# Parashu register map
Vendor: Shakti; Series: Shakti SoC
Shakti SoC, 32-bit RV32IMAC core on arty7 100T
CPU: Parashu, little endian
Registers are 32-bit, read-write, reset 0x0 unless marked. A register's access mark holds for its fields unless they carry their own. Offsets are from the block's base; lines under a group give offsets from that group; [hi:lo] are bit positions; {n}, {i} and the like mark numbered series; 'fields as' and 'values as' point back to an identical list; <NAME> marks a mode.

## Memory map
0x00011300 UART0 size 0x100 — Universal Asynchronous Receiver/Transmitter.
0x00011400 UART1 size 0x100 — Universal Asynchronous Receiver/Transmitter.
0x00011500 UART2 size 0x100 — Universal Asynchronous Receiver/Transmitter.
0x00020000 SPI0 size 0x100
0x00020100 SPI1 size 0x100
0x00030000 PWM0 size 0x100 — Pulse-Width Modulation.
0x00030100 PWM1 size 0x100
0x00030200 PWM2 size 0x100
0x00030300 PWM3 size 0x100
0x00030400 PWM4 size 0x100
0x00030500 PWM5 size 0x100
0x00040000 I2C0 size 0x100
0x00040100 GPIO0 size 0x1000 — General purpose input/output controller.
0x00041400 I2C1 size 0x100
0x0C000000 PLIC size 0x200008 — Platform-Level Interrupt Controller.
0x20000000 CLINT size 0x10000 — Core Local Interruptor.

## Interrupts
1 PWM0
2 PWM1
3 PWM2
4 PWM3
5 PWM4
6 PWM5
{n+7} GPIO_{n}_IRQ (GPIO0) (n=0..12)
20 GPIO_12_IRQ (GPIO0)
21 GPIO_14_IRQ (GPIO0)
22 GPIO_15_IRQ (GPIO0)
23 I2C0
24 I2C (I2C1)
25 UART0_IRQ (UART0)
26 UART1_IRQ (UART1)
27 UART1_IRQ (UART2)

## PLIC — Platform-Level Interrupt Controller.
Base 0x0C000000
{0x0+4i} PRIORITY[{i}] (i=0..51) — PLIC Interrupt Priority Register.
  [2:0] PRIORITY
{0xFFF+i} PENDING_{i} (i=1..3) — PLIC Interrupt Pending Register {i} Sources {8i-8} to {8i-1}.
0x1003 PENDING_4 — PLIC Interrupt Pending Register 4 Sources 24 to 27.
0x2000 ENABLE_1 — PLIC Interrupt Enable Register 1. Sources 0 to 7
0x2001 ENABLE_2 — PLIC Interrupt Enable Register 2. Sources 8 to 15
0x2002 ENABLED_3 — PLIC Interrupt Enable Register 3. Sources 16 to 23
0x2003 ENABLED_4 — PLIC Interrupt Enable Register 4. Sources 24 to 27
0x10000 THRESHOLD — PLIC Interrupt Priority Threshold Register.
  [2:0] THRESHOLD
0x10010 CLAIM — PLIC Claim/Complete Register.

## CLINT — Core Local Interruptor.
Base 0x20000000
0x00 MSIP — Machine Software Interrupt Pending Register.
0x4000 MTIMECMP — Machine Timer Compare Register.
0xBFF8 MTIME — Machine Timer Register.

## GPIO0 — General purpose input/output controller.
Base 0x00040100
0x00 DIRECTION 16-bit
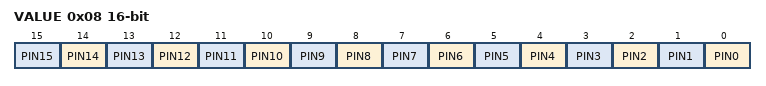
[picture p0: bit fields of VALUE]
0x08 VALUE 16-bit — Pin value.
  [n] PIN{n} (n=0..15)

## UART0 — Universal Asynchronous Receiver/Transmitter.
Base 0x00011300
Same registers: UART1 0x00011400, UART2 0x00011500
0x00 BAUDRATE
  [15:0] BAUDCOUNT
0x04 TXREGISTER — Transmit Data Register.
0x08 RXREGISTER — Receive Data Register.
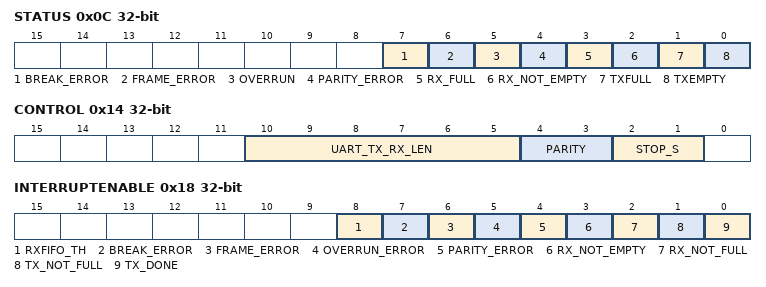
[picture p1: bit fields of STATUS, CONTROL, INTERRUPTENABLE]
0x0C STATUS — UART STATUS.
  [7] BREAK_ERROR, [6] FRAME_ERROR, [5] OVERRUN, [4] PARITY_ERROR, [3] RX_FULL, [2] RX_NOT_EMPTY, [1] TXFULL, [0] TXEMPTY
0x10 DELAY
0x14 CONTROL
  [10:5] UART_TX_RX_LEN, [4:3] PARITY, [2:1] STOP_S
0x18 INTERRUPTENABLE
  [8] RXFIFO_TH, [7] BREAK_ERROR, [6] FRAME_ERROR, [5] OVERRUN_ERROR, [4] PARITY_ERROR, [3] RX_NOT_EMPTY, [2] RX_NOT_FULL, [1] TX_NOT_FULL, [0] TX_DONE
0x1C IQC — Input Qualification Control Register
0x20 RXTHRESHOLD

## PWM0 — Pulse-Width Modulation.
Base 0x00030000
Same registers: PWM1 0x00030100, PWM2 0x00030200, PWM3 0x00030300, PWM4 0x00030400, PWM5 0x00030500
0x00 PERIOD — PWM Period Register.
0x04 DUTY — PWM Duty Register.
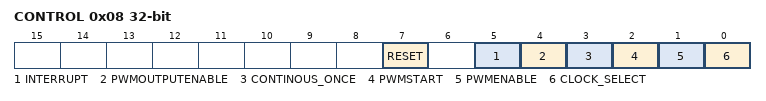
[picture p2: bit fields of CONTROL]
0x08 CONTROL — PWM Control Register.
  [7] RESET, [5] INTERRUPT, [4] PWMOUTPUTENABLE, [3] CONTINOUS_ONCE, [2] PWMSTART, [1] PWMENABLE, [0] CLOCK_SELECT
0x0C CLOCK — PWM CLOCK Register.
  [15:1] PWMPRESCALAR

## I2C0
Base 0x00040000
Same registers: I2C1 0x00041400
0x00 PRESCALE — I2C Prescale Register divides the System clock by (Prescale value + 1). This clock is used as clock input for I2C Serial Clock..
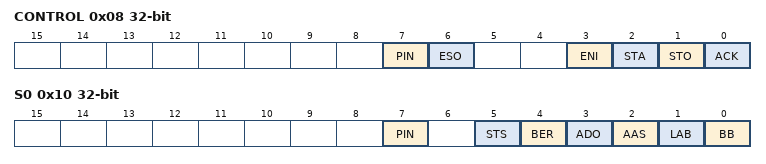
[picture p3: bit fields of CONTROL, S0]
0x08 CONTROL — Controls the I2C data transfer
  [7] PIN, [6] ESO, [3] ENI, [2] STA, [1] STO, [0] ACK
0x10 S0 — I2C Data Shift Register
  [7] PIN, [5] STS, [4] BER, [3] ADO, [2] AAS, [1] LAB, [0] BB
0x18 STATUS — I2C Status Register
0x38 SCL — I2C Clock Register

## SPI0
Base 0x00020000
Same registers: SPI1 0x00020100
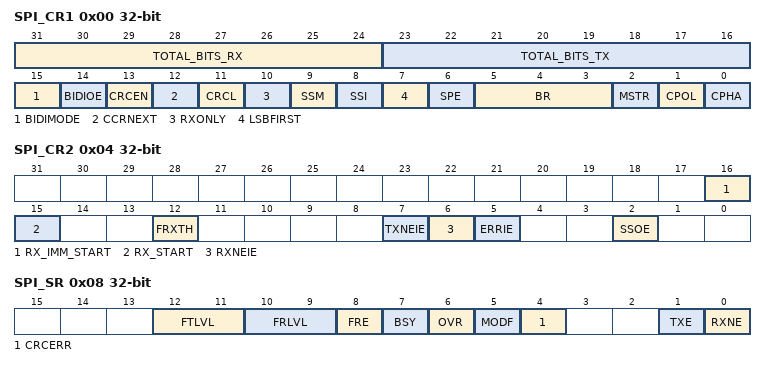
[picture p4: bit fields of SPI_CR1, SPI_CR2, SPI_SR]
0x00 SPI_CR1
  [31:24] TOTAL_BITS_RX, [23:16] TOTAL_BITS_TX, [15] BIDIMODE, [14] BIDIOE, [13] CRCEN, [12] CCRNEXT, [11] CRCL, [10] RXONLY, [9] SSM, [8] SSI, [7] LSBFIRST, [6] SPE, [5:3] BR, [2] MSTR, [1] CPOL, [0] CPHA
0x04 SPI_CR2
  [16] RX_IMM_START, [15] RX_START, [12] FRXTH, [7] TXNEIE, [6] RXNEIE, [5] ERRIE, [2] SSOE
0x08 SPI_SR
  [12:11] FTLVL, [10:9] FRLVL, [8] FRE, [7] BSY, [6] OVR, [5] MODF, [4] CRCERR, [1] TXE, [0] RXNE
{0x8+4i} SPI_DR{i} (i=1..5) — SPI Data Register {i}
